AUTOSAR XML (schema 4.0)
package /primatec/light/lceMaster
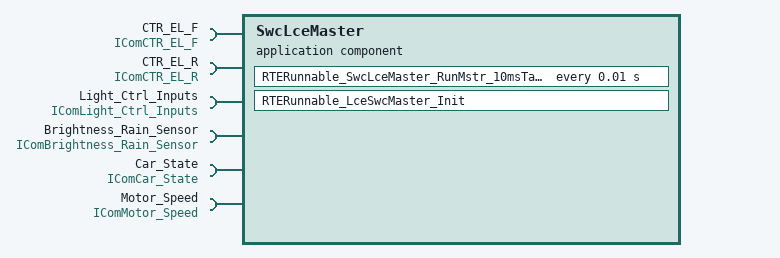
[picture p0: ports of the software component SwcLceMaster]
  application sw component type SwcLceMaster
    6 x require port:
      CTR_EL_F: required-interface=IComCTR_EL_F
      CTR_EL_R: required-interface=IComCTR_EL_R
      Light_Ctrl_Inputs: required-interface=IComLight_Ctrl_Inputs
      Brightness_Rain_Sensor: required-interface=IComBrightness_Rain_Sensor
      Car_State: required-interface=IComCar_State
      Motor_Speed: required-interface=IComMotor_Speed
    behavior SwcLceMaster_DefaultBehavior
      timing event periodRunnable_LceMaster10ms: start-on-event=RTERunnable_SwcLceMaster_RunMstr_10msTask, period=0.01
      runnable RTERunnable_LceSwcMaster_Init: symbol=RTERunnable_SwcLceMaster_Init
      runnable RTERunnable_SwcLceMaster_RunMstr_10msTask: can-be-invoked-concurrently=true
        data-receive-point-by-arguments:
          4 x access:
            DRPA_Light_Ctrl_Inputs_ST_LP_LIN: accessed-variable=Light_Ctrl_Inputs.ST_LP_LIN
            DRPA_Brightness_Rain_Sensor_ST_RB_LIN: accessed-variable=Brightness_Rain_Sensor.ST_RB_LIN
            DRPA_Car_State_VEH_ST: accessed-variable=Car_State.VEH_ST
            DRPA_Motor_Speed_Motor_Speed: accessed-variable=Motor_Speed.Motor_Speed
        data-receive-points-by-arguments:
          6 x access:
            DRPA_CTR_EL_F_CTR_FN_DR: accessed-variable=CTR_EL_F.CTR_FN_DR
            DRPA_comCTR_EL_F_CTR_FN_POS: accessed-variable=CTR_EL_F.CTR_FN_POS
            DRPA_comCTR_EL_F_CTR_FN_PAR: accessed-variable=CTR_EL_F.CTR_FN_PAR
            DRPA_CTR_EL_R_CTR_FN_DR: accessed-variable=CTR_EL_R.CTR_FN_DR
            DRPA_CTR_EL_R_CTR_FN_POS: accessed-variable=CTR_EL_R.CTR_FN_POS
            DRPA_CTR_EL_R_CTR_FN_PAR: accessed-variable=CTR_EL_R.CTR_FN_PAR
